# core_aon_secure register map
Vendor: Texas Instruments
Peripheral module from a debugger description file (folder CC35X1).
Registers are 32-bit, access per field, reset 0x0 unless marked. A register's access mark holds for its fields unless they carry their own. Offsets are as the file gives them; lines under a group give offsets from that group; [hi:lo] are bit positions; {n}, {i} and the like mark numbered series; 'fields as' and 'values as' point back to an identical list; <NAME> marks a mode.

## core_aon_secure
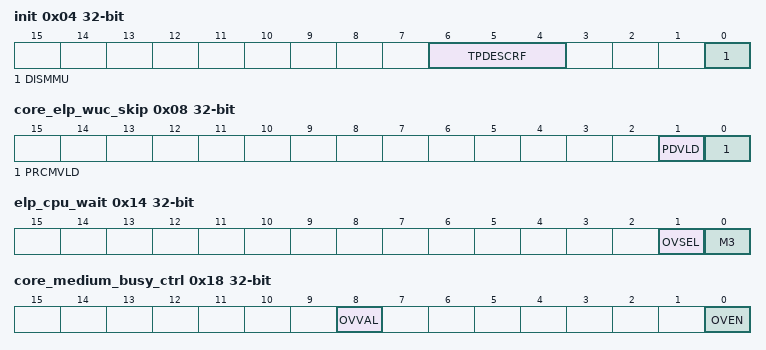
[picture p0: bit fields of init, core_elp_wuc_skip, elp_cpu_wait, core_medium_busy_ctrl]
0x04 init
  [6:4] TPDESCRF rw — TYPE DESCRF 0 - Descriptor FIFO memory (mem per bit) is initiated when getting out of reset (at power up or when back from sleep) 1 - Descriptor FIFO memory (mem per bit) is not initiated when getting out of reset (as it's held in retention) MEM_INIT_TYPE_DESCRF[0] = disable INIT of link_table MEM_INIT_TYPE_DESCRF[1] = disable INIT of queue_db MEM_INIT_TYPE_DESCRF[2] = disable INIT of seq_num
  [0] DISMMU rw — DISABLE MMU 0 - MMU memories, VLUT and MBLR are initiated when getting out of reset (at power up or when back from sleep) 1 - MMU memories, VLUT and MBLR are not initiated when getting out of reset (as they're held in retention)
0x08 core_elp_wuc_skip — WUC SKIP
  [1] PDVLD rw — POWER DOMAIN VALID Enable skip precise duration for Power Domain if wakup event type is '0': '0' - don't skip '1' - skip
  [0] PRCMVLD rw — PRCM VLD Enable skip precise duration for PRCM Shared UP if wakup event type is '0': '0' - don't skip '1' - skip
0x14 elp_cpu_wait reset not defined — CPU WAIT
  [1] OVSEL rw — OVERRIDE SELECTOR override selector for using the MMR of CPU wait or the ELP FSM '1' - use the MMR mem_m3_cpu_wait '0' - use ELP FSM
  [0] M3 rw — M3 The CPUWAIT allows the boot sequence of the processor M3 to be delayed. This is useful in the case where the Teal processor is used in a SoC, and the program code has to be loaded into SRAM first (e.g. via DMA under the control of another processor). In this case, instead of hold the processor in reset, we can use CPUWAIT de-assertion to defer the start up sequence and allow the system to start after the program code has been successfully loaded into the program SRAM.
0x18 core_medium_busy_ctrl — CORE MEDIUM BUSY CONTROL Medium busy AON override option towards IOMUX
  [8] OVVAL rw — OVERRIDE VALUE
  [0] OVEN rw — OVERRIDE ENABLE
0x1C elp_cfg_wakeup_type — CONFIG WAKE UP TYPE
  [24:0] VAL rw — VALUE Set 0 - Slow Wake up (precise WU). Set 1 - Fast Wake up (MX device, assume system is already active when event is triggered). Bit 0 : tmr_wakeup_req Bit 1 : hif_wakeup_int Bit 2 : gpio_wakeup_src[0] Bit 3 : gpio_wakeup_src[1] Bit 4 : evt_mng_m3_irq0 Bit 5 : evt_mng_m3_irq1 Bit 6 : evt_mng_m3_irq2 Bit 7 : evt_mng_m3_irq3 Bit 8 : evt_mng_m3_irq4 Bit 9 : evt_mng_m3_irq5 Bit 10 : evt_mng_m3_irq6 Bit 11 : evt_mng_m3_irq7 Bit 12 : evt_mng_m3_irq8 Bit 13 : evt_mng_m3_irq9 Bit 14 : doorbell0_m2_irq Bit 15 : doorbell1_m2_irq Bit 16 : doorbell2_m2_irq Bit 17 : doorbell3_m2_irq Bit 18 : doorbell4_m2_irq Bit 19 : doorbell5_m2_irq Bit 20 : doorbell6_m2_irq Bit 21 : doorbell7_m2_irq Bit 22 : mem_ns_sw_interrupt_to_cm3 Bit 23 : mem_sec_sw_interrupt_to_cm3 Bit 24 : debugss_core_forceactive
0x24 elp_cfg_wicsense reset 0x2000001 — CONFIG WICSENSE
  [24:0] VAL rw — VALUE Set 1 - Enable wakeup source. Set 0 - Disable wakeup source. Bit 0 : tmr_wakeup_req Bit 1 : hif_wakeup_int Bit 2 : gpio_wakeup_src[0] Bit 3 : gpio_wakeup_src[1] Bit 4 : evt_mng_m3_irq0 Bit 5 : evt_mng_m3_irq1 Bit 6 : evt_mng_m3_irq2 Bit 7 : evt_mng_m3_irq3 Bit 8 : evt_mng_m3_irq4 Bit 9 : evt_mng_m3_irq5 Bit 10 : evt_mng_m3_irq6 Bit 11 : evt_mng_m3_irq7 Bit 12 : evt_mng_m3_irq8 Bit 13 : evt_mng_m3_irq9 Bit 14 : doorbell0_m2_irq Bit 15 : doorbell1_m2_irq Bit 16 : doorbell2_m2_irq Bit 17 : doorbell3_m2_irq Bit 18 : doorbell4_m2_irq Bit 19 : doorbell5_m2_irq Bit 20 : doorbell6_m2_irq Bit 21 : doorbell7_m2_irq Bit 22 : mem_ns_sw_interrupt_to_cm3 Bit 23 : mem_sec_sw_interrupt_to_cm3 Bit 24 : debugss_core_forceactive
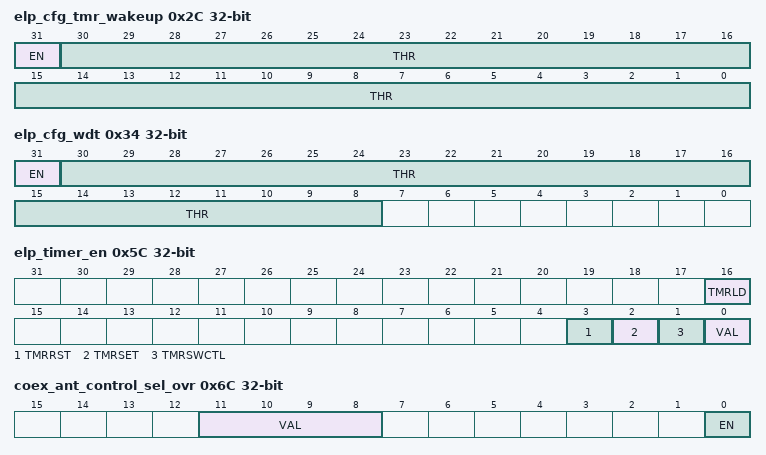
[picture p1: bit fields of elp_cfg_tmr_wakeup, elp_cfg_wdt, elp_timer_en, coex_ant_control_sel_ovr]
0x2C elp_cfg_tmr_wakeup rw — CONFIG TIMER WAKEUP
  [31] EN — ENABLE Set 1 - Enable BCN threshold IRQ. Set 0 - Otherwise. Timer is kicked upon moving from ACTIVE to POWER DOWN.
  [30:0] THR — THRESHOLD Upon reaching this value wakeup event is generated towards the WUC (if not masked in WICSENSE). Resolution slow clock cycles. value must be greater than 1
0x34 elp_cfg_wdt — CONFIG WATCHDOG TIMER
  [31] EN rw — ENABLE Set 1 - Enable WDT. Set 0 - Disable WDT.
  [30:8] THR rw — THRESHOLD Upon reaching this value wakeup event is generated towards the WUC (if not masked in WICSENSE). Resolution slow clock cycles (min val ~8ms). value must be greater than 1
0x38 elp_wakeup_req ro — WAKEUP REQUEST Bit 0 : wdt_wakeup_req
  [24:0] EVTVAL — EVENT VALUE Bit 0 : tmr_wakeup_req Bit 1 : hif_wakeup_int Bit 2 : gpio_wakeup_src[0] Bit 3 : gpio_wakeup_src[1] Bit 4 : evt_mng_m3_irq0 Bit 5 : evt_mng_m3_irq1 Bit 6 : evt_mng_m3_irq2 Bit 7 : evt_mng_m3_irq3 Bit 8 : evt_mng_m3_irq4 Bit 9 : evt_mng_m3_irq5 Bit 10 : evt_mng_m3_irq6 Bit 11 : evt_mng_m3_irq7 Bit 12 : evt_mng_m3_irq8 Bit 13 : evt_mng_m3_irq9 Bit 14 : doorbell0_m2_irq Bit 15 : doorbell1_m2_irq Bit 16 : doorbell2_m2_irq Bit 17 : doorbell3_m2_irq Bit 18 : doorbell4_m2_irq Bit 19 : doorbell5_m2_irq Bit 20 : doorbell6_m2_irq Bit 21 : doorbell7_m2_irq Bit 22 : mem_ns_sw_interrupt_to_cm3 Bit 23 : mem_sec_sw_interrupt_to_cm3 Bit 24 : debugss_core_forceactive
0x40 elp_cfg_short_sleep — CONFIG SHORT SLEEP Hold the device clock request high, to save fref setting time during power up.
  [0] CLKREQ rw — CLOCK REQUEST
0x54 elp_fast_clk_from_arm_cmd ro — FAST CLOCK FROM ARM CMD Latched counter value reflecting the number of fast clocks (clk_core_clk) from rise of SLEEPDEEP indication until ELP WUC start power down sequence. This value should capture the uncertainty of 2-3 slow clocks of synchronization of ARM CMD.
  [15:0] VAL — VALUE
0x58 elp_sleep_time_slow ro — SLEEP TIME SLOW Sleep time value from last ELP sleep entry (slow clock synced ARM CMD). Slow Clock - Reflects the number of slow clocks in ELP timer.
  [31:0] CLK — CLOCK read clear
0x5C elp_timer_en — TIMER ENABLE 1 - ELP Timer is running. 0 - Otherwise.
  [16] TMRLD wo — TIMER LOAD setting this bit will load the value 2 to the timer
  [3] TMRRST rw — TIMER RESET setting this bit will stop the timer
  [2] TMRSET rw — TIMER SET starts the timer
  [1] TMRSWCTL rw — TIMER SOFTWARE CONTROL '0' - HW CTRL '1' - SW CTRL.
  [0] VAL ro — VALUE
0x6C coex_ant_control_sel_ovr — COEX ANTENNA CONTROL SELECT OVERRIDE
  [11:8] VAL rw — VALUE
  [0] EN rw — ENABLE
0x74 elp_sleep_time_fast ro — SLEEP TIME FAST Sleep time value from last ELP sleep entry (slow clock synced ARM CMD). Fast Clock - Reflects the number of fast clocks from last Slow clock rise until OCP Read. Note, fast counter value is latched upon OCP Read of ELP_SLEEP_TIME_SLOW. Counts up t0 51 microsecond.
  [10:0] CLK — CLOCK
0x9C elp_gpio_wakeup_and_irq rw — GPIO WAKEUP AND LOGIC IRQ
  [31:0] _0T31BM — 0 TO 31 BITMASK select 0-31 GPIOs as wakeup source.
0xA0 elp_gpio_wakeup_or_irq rw — GPIO WAKEUP OR LOGIC IRQ
  [31:0] _0T31BM — 0 TO 31 BITMASK select 0-31 GPIOs as wakeup source.
0xA4 elp_gpio_wakeup_and_irq_1 — GPIO WAKEUP AND LOGIC IRQ 1
  [12:0] _32T44BM rw — 32 TO 44 BITMASK select 32-44 GPIOs as wakeup source.
0xA8 elp_gpio_wakeup_or_irq_1 — GPIO WAKEUP OR LOGIC IRQ 1
  fields as elp_gpio_wakeup_and_irq_1
0xAC elp_tmr_wakeup_req_clr — TIMER WAKEUP REQUEST
  [0] CLR wo — CLEAR write clear
0xB0 elp_wdt_req_clr — WATCHDOG TIMER REQUEST
  [0] CLR wo — CLEAR write clear
0xD8 force_core_on — FORCE CORE
  [0] ON rw — ON host to write here '1' to keep the core awake
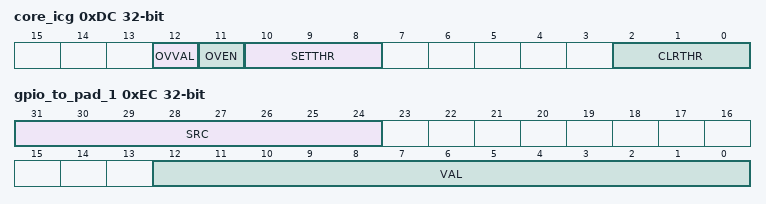
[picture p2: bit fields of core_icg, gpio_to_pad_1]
0xDC core_icg
  [12] OVVAL rw — OVERRIDE VALUE once override en is '1', the ICG will work according to the below- '0' - CORE ICG disable '1' - CORE ICG enable
  [11] OVEN rw — OVERRIDE ENABLE use Override value for core ICG- '0' - don't use override '1' - use override
  [10:8] SETTHR rw — SET THRESHOLD Delay Counter value to EN CORE clk- The time we will wait from the moment M3 CLK Enabled
  [2:0] CLRTHR rw — CLEAR THRESHOLD Delay Counter value to gate CORE clk- The time we will wait from the moment M3 CLK stopped
0xE0 core_wuc_state ro reset 0x24 — CORE WUC
  [2:0] STA — STATE 3'b000 - PD_PWR_DN 3'b001 - SHARED_UP 3'b010 - PD_PWR_UP 3'b011 - ACTIVE 3'b100 - DEEPSLEEP
0xE4 nab_host_irq_cfg — NAB HOST IRQ CONFIG
  [0] POL rw — POLARITY "1" for negative polarity "0" for positive polarity (GuyS: in order to preserve this at sleep (retention) - ISO latch needs to be implemented. Alternatively, move this polarity cfg bit to upper H/W layer above Nab)
0xE8 gpio_to_pad_0 rw
  [31:0] VAL — VALUE SW value to be reflected on GPIO to pad.
0xEC gpio_to_pad_1
  [31:24] SRC rw — SOURCE Set 1 - Used HW source. Set 0 - Used SW source. bit[0] - GPIO3 bit[1] - GPIO4 bit[2] - GPIO5 bit[3] - GPIO6 bit[4] - GPIO26 bit[5] - GPIO27 bit[6] - GPIO28 bit[7] - GPIO29
  [12:0] VAL rw — VALUE SW value to be reflected on GPIO to pad.
0xF8 gpio_oen_cfg_0 rw — GPIO OUT ENABLE CONFIG 0
  [31:0] VAL — VALUE Set 0 - Output. Set 1 - Input.
0xFC gpio_oen_cfg_1 — GPIO OUT ENABLE CONFIG 1
  [12:0] VAL rw — VALUE Set 0 - Output. Set 1 - Input.
